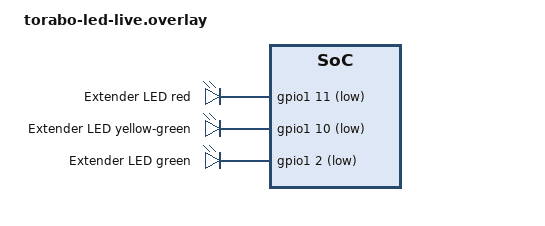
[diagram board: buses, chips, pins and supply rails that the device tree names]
/*
 * torabo-led-live — the 3-colour extender LED on the CENTRAL half, driven by the
 * runtime rule table instead of the hardcoded status_led_ext behaviour.
 *
 * Cathode-driven common-anode array whose anode rides the extender pad's POW rail
 * (P0.24) — so use together with the ext pad snippet, which powers that rail.
 * GPIO_ACTIVE_LOW so gpio_pin_set_dt(_, 1) lights a channel.
 *
 *   red          = P1.11
 *   yellow-green = P1.10
 *   "green"      = P1.02   (datasheet labels this element Y; swap with yellow-green
 *                           here if the tint looks off on the real board)
 */

#include <zephyr/dt-bindings/gpio/gpio.h>

/ {
    torabo_led_ext {
        compatible = "gpio-leds";
        ledx_red: ledx_red {
            gpios = <&gpio1 11 GPIO_ACTIVE_LOW>;
            label = "Extender LED red";
        };
        ledx_yg: ledx_yg {
            gpios = <&gpio1 10 GPIO_ACTIVE_LOW>;
            label = "Extender LED yellow-green";
        };
        ledx_grn: ledx_grn {
            gpios = <&gpio1 2 GPIO_ACTIVE_LOW>;
            label = "Extender LED green";
        };
    };
};
